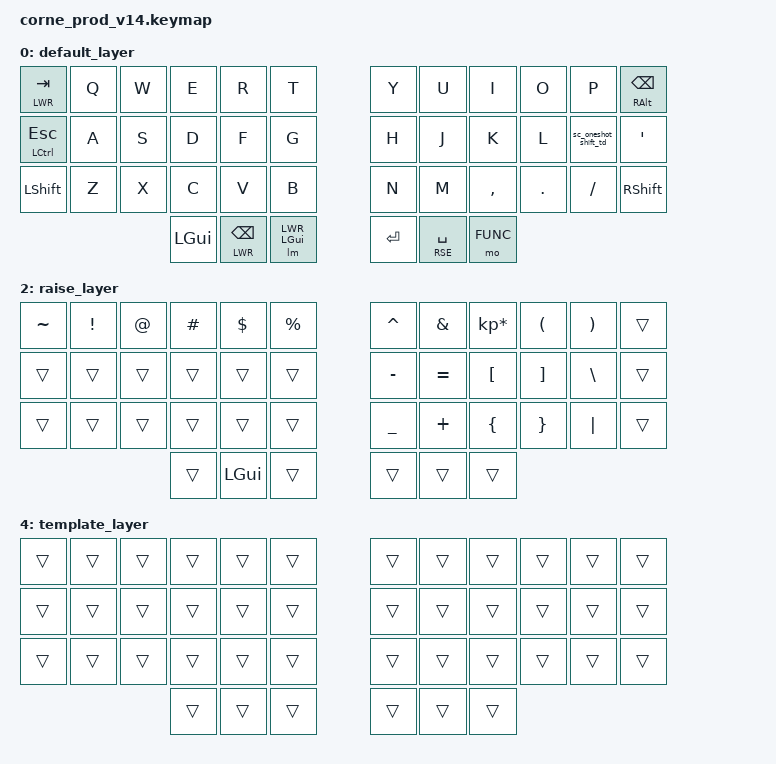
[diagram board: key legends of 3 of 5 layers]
/*
 * Copyright (c) 2020 The ZMK Contributors
 *
 * SPDX-License-Identifier: MIT
 *
 * Reference: https://zmk.dev/docs/keymaps/behaviors/key-press
 *
 */

#include <behaviors.dtsi>
#include <dt-bindings/zmk/keys.h>
#include <dt-bindings/zmk/bt.h>
#include <dt-bindings/zmk/rgb.h>

&led_strip {
    chain-length = <27>;
};

// Define the custom macro
// reference: https://zmk.dev/docs/keymaps/behaviors/macros
/ {
    macros {
        // switch input method
        macos_input: macos_input {
            compatible = "zmk,behavior-macro";
            #binding-cells = <0>;
            bindings
                = <&macro_press &kp LCTRL>
                , <&macro_press &kp LALT>
                , <&macro_tap &kp SPACE>
                , <&macro_release &kp LALT>
                , <&macro_release &kp LCTRL>
                ;
        };
        // alt_backspace ALT_BS
        alt_backspace: alt_backspace {
            compatible = "zmk,behavior-macro";
            #binding-cells = <0>;
            bindings
                = <&macro_press &kp LALT>
                , <&macro_tap &kp BSPC>
                , <&macro_release &kp LALT>
                ;
        };
        // MAC_SC
        macos_screenshot: macos_screenshot {
            compatible = "zmk,behavior-macro";
            #binding-cells = <0>;
            bindings
                = <&macro_press &kp LGUI>
                , <&macro_press &kp LCTRL>
                , <&macro_press &kp LSHFT>
                , <&macro_tap &kp N4>
                , <&macro_release &kp LSHFT>
                , <&macro_release &kp LCTRL>
                , <&macro_release &kp LGUI>
                ;
        };
        // MAC_SA
        macos_screenshot_with_annotation: macos_screenshot_with_annotation {
            compatible = "zmk,behavior-macro";
            #binding-cells = <0>;
            bindings
                = <&macro_press &kp LGUI>
                , <&macro_press &kp LSHFT>
                , <&macro_tap &kp N4>
                , <&macro_release &kp LSHFT>
                , <&macro_release &kp LGUI>
                ;
        };
        ctrl_alt_left: ctrl_alt_left {
            compatible = "zmk,behavior-macro";
            #binding-cells = <0>;
            bindings
                = <&macro_press &kp LCTRL>
                , <&macro_press &kp LALT>
                , <&macro_tap &kp LEFT>
                , <&macro_release &kp LALT>
                , <&macro_release &kp LCTRL>
                ;
        };
        ctrl_alt_right: ctrl_alt_right {
            compatible = "zmk,behavior-macro";
            #binding-cells = <0>;
            bindings
                = <&macro_press &kp LCTRL>
                , <&macro_press &kp LALT>
                , <&macro_tap &kp RIGHT>
                , <&macro_release &kp LALT>
                , <&macro_release &kp LCTRL>
                ;
        };
        ctrl_alt_up: ctrl_alt_up {
            compatible = "zmk,behavior-macro";
            #binding-cells = <0>;
            bindings
                = <&macro_press &kp LCTRL>
                , <&macro_press &kp LALT>
                , <&macro_tap &kp UP>
                , <&macro_release &kp LALT>
                , <&macro_release &kp LCTRL>
                ;
        };
        ctrl_alt_down: ctrl_alt_down {
            compatible = "zmk,behavior-macro";
            #binding-cells = <0>;
            bindings
                = <&macro_press &kp LCTRL>
                , <&macro_press &kp LALT>
                , <&macro_tap &kp DOWN>
                , <&macro_release &kp LALT>
                , <&macro_release &kp LCTRL>
                ;
        };
        ctrl_alt_enter: ctrl_alt_enter {
            compatible = "zmk,behavior-macro";
            #binding-cells = <0>;
            bindings
                = <&macro_press &kp LCTRL>
                , <&macro_press &kp LALT>
                , <&macro_tap &kp RET>
                , <&macro_release &kp LALT>
                , <&macro_release &kp LCTRL>
                ;
        };
        // cmd_grave
        cmd_grave: cmd_grave {
            compatible = "zmk,behavior-macro";
            #binding-cells = <0>;
            bindings
                = <&macro_press &kp LGUI>
                , <&macro_tap &kp GRAVE>
                , <&macro_release &kp LGUI>
                ;
        };
        // cmd_1
        cmd_1: cmd_1 {
            compatible = "zmk,behavior-macro";
            #binding-cells = <0>;
            bindings
                = <&macro_press &kp LGUI>
                , <&macro_tap &kp N1>
                , <&macro_release &kp LGUI>
                ;
        };
        // cmd_2
        cmd_2: cmd_2 {
            compatible = "zmk,behavior-macro";
            #binding-cells = <0>;
            bindings
                = <&macro_press &kp LGUI>
                , <&macro_tap &kp N2>
                , <&macro_release &kp LGUI>
                ;
        };
        // cmd_3
        cmd_3: cmd_3 {
            compatible = "zmk,behavior-macro";
            #binding-cells = <0>;
            bindings
                = <&macro_press &kp LGUI>
                , <&macro_tap &kp N3>
                , <&macro_release &kp LGUI>
                ;
        };
        // cmd_4
        cmd_4: cmd_4 {
            compatible = "zmk,behavior-macro";
            #binding-cells = <0>;
            bindings
                = <&macro_press &kp LGUI>
                , <&macro_tap &kp N4>
                , <&macro_release &kp LGUI>
                ;
        };
        // cmd_5
        cmd_5: cmd_5 {
            compatible = "zmk,behavior-macro";
            #binding-cells = <0>;
            bindings
                = <&macro_press &kp LGUI>
                , <&macro_tap &kp N5>
                , <&macro_release &kp LGUI>
                ;
        };
        /**
        * Temporarily switches to a layer (`&mo`) while a modifier is held.
        * Analogous to QMK's `LM()`, using a parameterized macro.
        *
        * Params:
        *  1. Layer to switch to
        *  2. Modifier to press while layer is active
        *
        * Example:
        *  `&lm NUM_LAYER LSHIFT`
        */
        lm: lm {
            compatible = "zmk,behavior-macro-two-param";
            wait-ms = <0>;
            tap-ms = <0>;
            #binding-cells = <2>;
            bindings
                = <&macro_param_1to1>
                , <&macro_press &mo MACRO_PLACEHOLDER>
                , <&macro_param_2to1>
                , <&macro_press &kp MACRO_PLACEHOLDER>
                , <&macro_pause_for_release>
                , <&macro_param_2to1>
                , <&macro_release &kp MACRO_PLACEHOLDER>
                , <&macro_param_1to1>
                , <&macro_release &mo MACRO_PLACEHOLDER>
                ;
        };
    };
};

/ {
  behaviors {
    sc_oneshot_shift_td: sc_oneshot_shift_td {
      compatible = "zmk,behavior-tap-dance";
      label = "SC_OS_SHIFT_TD";
      #binding-cells = <0>;

      bindings = <
        &kp SEMI     /* 1 tap -> ; */
        &sk LSHFT    /* 2 taps -> one-shot Shift (next key shifted) */
      >;

      tapping-term-ms = <200>;
    };
  };
};

#define DEFAULT 0
#define DFT 0
#define LWR 1
#define RSE 2
#define FUNC 3

#define mac_sc macos_screenshot
#define mac_sca macos_screenshot_with_annotation
#define mac_in macos_input

/ {
        keymap {
                compatible = "zmk,keymap";

                default_layer {
// -----------------------------------------------------------------------------------------
// | TAB / LWR (single-hand) |  Q  |  W  |  E   |  R         |  T     | | Y   |  U        |  I       |  O  |  P  | BSPC / RALT |
// | ESC / LCTRL             |  A  |  S  |  D   |  F         |  G     | | H   |  J        |  K       |  L  | sc_oneshot_shift_td | '           |
// | LSHFT                   |  Z  |  X  |  C   |  V         |  B     | | N   |  M        |  ,       |  .  |  /  | RSHFT       |
//                                       | LGUI | BSPC / LWR | LWR + LGUI | | ENT | SPC / RSE | FUNC |
                        bindings = <
   &lt LWR TAB   &kp Q &kp W &kp E    &kp R        &kp T        &kp Y   &kp U         &kp I     &kp O   &kp P    &mt RALT BSPC
   &mt LCTRL ESC &kp A &kp S &kp D    &kp F        &kp G        &kp H   &kp J         &kp K     &kp L   &sc_oneshot_shift_td &kp SQT
   &kp LSHFT     &kp Z &kp X &kp C    &kp V        &kp B        &kp N   &kp M         &kp COMMA &kp DOT &kp FSLH &kp RSHFT
                             &kp LGUI &lt LWR BSPC &lm LWR LGUI &kp RET &lt RSE SPACE &mo FUNC
                        >;
                };
                lower_layer {
// -----------------------------------------------------------------------------------------
// | ` / LGUI (single-hand) | 1     | 2      |  3    |  4     | 5 | |  6   |  7   | 8  |  9  |  0  |  |
// |                        |mac_sc |mac_sca | enter | space  |   | | LFT  | DWN  | UP | RGT |     |  |
// |                        |       |        |       |        |   | |      |      |    |     |     |  |
//                                  |        |       |        |   | | RGUI |      |
                        bindings = <
   &mt LGUI GRAVE &kp N1  &kp N2   &kp N3  &kp N4    &kp N5  &kp N6   &kp N7   &kp N8 &kp N9    &kp N0 &trans
   &trans         &mac_sc &mac_sca &kp RET &kp SPACE &trans  &kp LEFT &kp DOWN &kp UP &kp RIGHT &trans &trans
   &trans         &trans  &trans   &trans  &trans    &trans  &trans   &trans   &trans &trans    &trans
                          &trans   &trans  &trans    &trans  &kp RGUI &trans
                        >;
                };
                raise_layer {
// -----------------------------------------------------------------------------------------
// | ~ | ! | @ | # | $    | % |  | ^ |  &  |  *  |  (  |  )  |      |
// |   |   |   |   |      |   |  | - |  =  |  [  |  ]  |  \  |      |
// |   |   |   |   |      |   |  | _ |  +  |  {  |  }  | "|" |      |
//             |   | LGUI |   |  |   |     |     |
                        bindings = <
   &kp TILDE &kp EXCL &kp AT &kp HASH &kp DLLR &kp PRCNT &kp CARET &kp AMPS  &kp KP_MULTIPLY &kp LPAR &kp RPAR &trans
   &trans    &trans   &trans &trans   &trans   &trans    &kp MINUS &kp EQUAL &kp LBKT        &kp RBKT &kp BSLH &trans
   &trans    &trans   &trans &trans   &trans   &trans    &kp UNDER &kp PLUS  &kp LBRC        &kp RBRC &kp PIPE &trans
                             &trans   &kp LGUI &trans    &trans    &trans    &trans
                        >;
                };
                func_layer {
// -----------------------------------------------------------------------------------------
// |   | BT0   | BT1      |BT2      | BT3   | BT4   | BTCLR   | |  |  |  |  |  |
// |   |       |          |         |       |       |         | |  |  |  |  |  |
// |   |RGB_TOG| RGB_EFF  | RGB_HUI |RGB_HUD|       | QK_BOOT | |  |  |  |  |  |
//                        |         |       |       |         | |  |  |
                        bindings = <
   &trans &bt BT_SEL 0 &bt BT_SEL 1 &bt BT_SEL 2 &bt BT_SEL 3 &bt BT_SEL 4 &bt BT_CLR &trans &trans &trans &trans &trans &trans
   &trans &trans &trans &trans &trans &trans &trans &trans &trans &trans &trans &trans
   &trans &rgb_ug RGB_TOG &rgb_ug RGB_EFF &rgb_ug RGB_HUI &rgb_ug RGB_HUD &trans &bootloader &trans &trans &trans &trans &trans
                        &trans &trans &trans &trans &trans &trans
                        >;
                };
                template_layer {
// -----------------------------------------------------------------------------------------
// | | | | | | | | | | | | | |
// | | | | | | | | | | | | | |
// | | | | | | | | | | | | | |
//       | | | | | | | |
                        bindings = <
   &trans &trans &trans &trans &trans &trans &trans &trans &trans &trans &trans &trans
   &trans &trans &trans &trans &trans &trans &trans &trans &trans &trans &trans &trans
   &trans &trans &trans &trans &trans &trans &trans &trans &trans &trans &trans &trans
                        &trans &trans &trans &trans &trans &trans
                        >;
                };
        };
};
